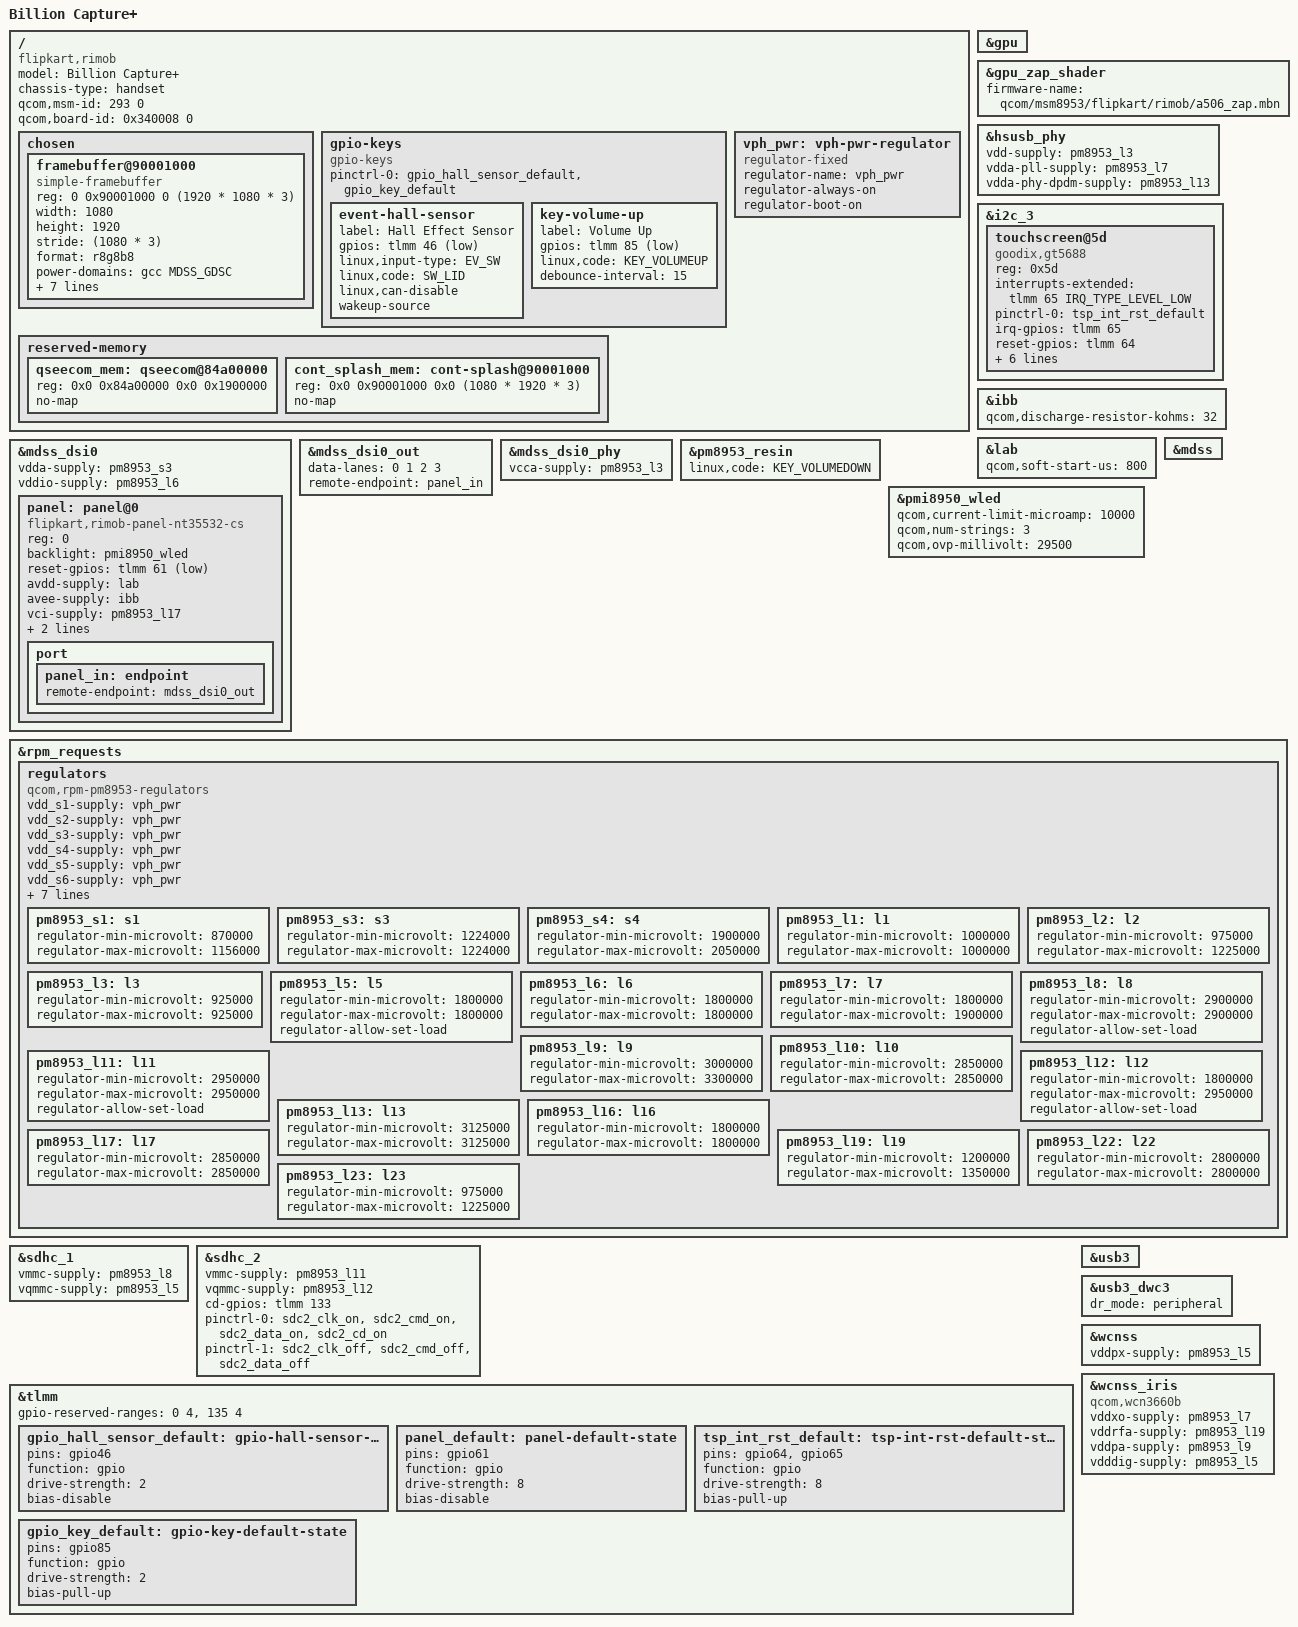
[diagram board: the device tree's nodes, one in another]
// SPDX-License-Identifier: BSD-3-Clause
/*
 * Copyright (c) 2025, Cristian Cozzolino
 */
/dts-v1/;

#include "msm8953.dtsi"
#include "pm8953.dtsi"
#include "pmi8950.dtsi"

/delete-node/ &cont_splash_mem;
/delete-node/ &qseecom_mem;

/ {
	model = "Billion Capture+";
	compatible = "flipkart,rimob", "qcom,msm8953";
	chassis-type = "handset";
	qcom,msm-id = <293 0>;
	qcom,board-id = <0x340008 0>;

	chosen {
		#address-cells = <2>;
		#size-cells = <2>;
		ranges;

		framebuffer@90001000 {
			compatible = "simple-framebuffer";
			reg = <0 0x90001000 0 (1920 * 1080 * 3)>;

			width = <1080>;
			height = <1920>;
			stride = <(1080 * 3)>;
			format = "r8g8b8";

			power-domains = <&gcc MDSS_GDSC>;

			clocks = <&gcc GCC_MDSS_AHB_CLK>,
				 <&gcc GCC_MDSS_AXI_CLK>,
				 <&gcc GCC_MDSS_VSYNC_CLK>,
				 <&gcc GCC_MDSS_MDP_CLK>,
				 <&gcc GCC_MDSS_BYTE0_CLK>,
				 <&gcc GCC_MDSS_PCLK0_CLK>,
				 <&gcc GCC_MDSS_ESC0_CLK>;
		};
	};

	gpio-keys {
		compatible = "gpio-keys";

		pinctrl-0 = <&gpio_hall_sensor_default>, <&gpio_key_default>;
		pinctrl-names = "default";

		event-hall-sensor {
			label = "Hall Effect Sensor";
			gpios = <&tlmm 46 GPIO_ACTIVE_LOW>;
			linux,input-type = <EV_SW>;
			linux,code = <SW_LID>;
			linux,can-disable;
			wakeup-source;
		};

		key-volume-up {
			label = "Volume Up";
			gpios = <&tlmm 85 GPIO_ACTIVE_LOW>;
			linux,code = <KEY_VOLUMEUP>;
			debounce-interval = <15>;
		};
	};

	reserved-memory {
		qseecom_mem: qseecom@84a00000 {
			reg = <0x0 0x84a00000 0x0 0x1900000>;
			no-map;
		};

		cont_splash_mem: cont-splash@90001000 {
			reg = <0x0 0x90001000 0x0 (1080 * 1920 * 3)>;
			no-map;
		};
	};

	vph_pwr: vph-pwr-regulator {
		compatible = "regulator-fixed";
		regulator-name = "vph_pwr";
		regulator-always-on;
		regulator-boot-on;
	};
};

&gpu {
	status = "okay";
};

&gpu_zap_shader {
	firmware-name = "qcom/msm8953/flipkart/rimob/a506_zap.mbn";
};

&hsusb_phy {
	vdd-supply = <&pm8953_l3>;
	vdda-pll-supply = <&pm8953_l7>;
	vdda-phy-dpdm-supply = <&pm8953_l13>;

	status = "okay";
};

&i2c_3 {
	status = "okay";

	touchscreen@5d {
		compatible = "goodix,gt5688";
		reg = <0x5d>;

		interrupts-extended = <&tlmm 65 IRQ_TYPE_LEVEL_LOW>;

		pinctrl-0 = <&tsp_int_rst_default>;
		pinctrl-names = "default";

		irq-gpios = <&tlmm 65 GPIO_ACTIVE_HIGH>;
		reset-gpios = <&tlmm 64 GPIO_ACTIVE_HIGH>;

		VDDIO-supply = <&pm8953_l6>;
		AVDD28-supply = <&pm8953_l10>;

		touchscreen-size-x = <1080>;
		touchscreen-size-y = <1920>;
		touchscreen-inverted-x;
		touchscreen-inverted-y;
	};
};

&ibb {
	qcom,discharge-resistor-kohms = <32>;
};

&lab {
	qcom,soft-start-us = <800>;
};

&mdss {
	status = "okay";
};

&mdss_dsi0 {
	vdda-supply = <&pm8953_s3>;
	vddio-supply = <&pm8953_l6>;

	status = "okay";

	panel: panel@0 {
		compatible = "flipkart,rimob-panel-nt35532-cs";
		reg = <0>;

		backlight = <&pmi8950_wled>;
		reset-gpios = <&tlmm 61 GPIO_ACTIVE_LOW>;
		avdd-supply = <&lab>;
		avee-supply = <&ibb>;
		vci-supply = <&pm8953_l17>;
		vddi-supply = <&pm8953_l6>;

		pinctrl-0 = <&panel_default>;
		pinctrl-names = "default";

		port {
			panel_in: endpoint {
				remote-endpoint = <&mdss_dsi0_out>;
			};
		};
	};
};

&mdss_dsi0_out {
	data-lanes = <0 1 2 3>;
	remote-endpoint = <&panel_in>;
};

&mdss_dsi0_phy {
	vcca-supply = <&pm8953_l3>;

	status = "okay";
};

&pm8953_resin {
	linux,code = <KEY_VOLUMEDOWN>;
	status = "okay";
};

&pmi8950_wled {
	qcom,current-limit-microamp = <10000>;
	qcom,num-strings = <3>;
	qcom,ovp-millivolt = <29500>;

	status = "okay";
};

&rpm_requests {
	regulators {
		compatible = "qcom,rpm-pm8953-regulators";
		vdd_s1-supply = <&vph_pwr>;
		vdd_s2-supply = <&vph_pwr>;
		vdd_s3-supply = <&vph_pwr>;
		vdd_s4-supply = <&vph_pwr>;
		vdd_s5-supply = <&vph_pwr>;
		vdd_s6-supply = <&vph_pwr>;
		vdd_s7-supply = <&vph_pwr>;
		vdd_l1-supply = <&pm8953_s3>;
		vdd_l2_l3-supply = <&pm8953_s3>;
		vdd_l4_l5_l6_l7_l16_l19-supply = <&pm8953_s4>;
		vdd_l8_l11_l12_l13_l14_l15-supply = <&vph_pwr>;
		vdd_l9_l10_l17_l18_l22-supply = <&vph_pwr>;
		vdd_l23-supply = <&pm8953_s3>;

		pm8953_s1: s1 {
			regulator-min-microvolt = <870000>;
			regulator-max-microvolt = <1156000>;
		};

		pm8953_s3: s3 {
			regulator-min-microvolt = <1224000>;
			regulator-max-microvolt = <1224000>;
		};

		pm8953_s4: s4 {
			regulator-min-microvolt = <1900000>;
			regulator-max-microvolt = <2050000>;
		};

		pm8953_l1: l1 {
			regulator-min-microvolt = <1000000>;
			regulator-max-microvolt = <1000000>;
		};

		pm8953_l2: l2 {
			regulator-min-microvolt = <975000>;
			regulator-max-microvolt = <1225000>;
		};

		pm8953_l3: l3 {
			regulator-min-microvolt = <925000>;
			regulator-max-microvolt = <925000>;
		};

		pm8953_l5: l5 {
			regulator-min-microvolt = <1800000>;
			regulator-max-microvolt = <1800000>;
			regulator-allow-set-load;
		};

		pm8953_l6: l6 {
			regulator-min-microvolt = <1800000>;
			regulator-max-microvolt = <1800000>;
		};

		pm8953_l7: l7 {
			regulator-min-microvolt = <1800000>;
			regulator-max-microvolt = <1900000>;
		};

		pm8953_l8: l8 {
			regulator-min-microvolt = <2900000>;
			regulator-max-microvolt = <2900000>;
			regulator-allow-set-load;
		};

		pm8953_l9: l9 {
			regulator-min-microvolt = <3000000>;
			regulator-max-microvolt = <3300000>;
		};

		pm8953_l10: l10 {
			regulator-min-microvolt = <2850000>;
			regulator-max-microvolt = <2850000>;
		};

		pm8953_l11: l11 {
			regulator-min-microvolt = <2950000>;
			regulator-max-microvolt = <2950000>;
			regulator-allow-set-load;
		};

		pm8953_l12: l12 {
			regulator-min-microvolt = <1800000>;
			regulator-max-microvolt = <2950000>;
			regulator-allow-set-load;
		};

		pm8953_l13: l13 {
			regulator-min-microvolt = <3125000>;
			regulator-max-microvolt = <3125000>;
		};

		pm8953_l16: l16 {
			regulator-min-microvolt = <1800000>;
			regulator-max-microvolt = <1800000>;
		};

		pm8953_l17: l17 {
			regulator-min-microvolt = <2850000>;
			regulator-max-microvolt = <2850000>;
		};

		pm8953_l19: l19 {
			regulator-min-microvolt = <1200000>;
			regulator-max-microvolt = <1350000>;
		};

		pm8953_l22: l22 {
			regulator-min-microvolt = <2800000>;
			regulator-max-microvolt = <2800000>;
		};

		pm8953_l23: l23 {
			regulator-min-microvolt = <975000>;
			regulator-max-microvolt = <1225000>;
		};
	};
};

&sdhc_1 {
	vmmc-supply = <&pm8953_l8>;
	vqmmc-supply = <&pm8953_l5>;

	status = "okay";
};

&sdhc_2 {
	vmmc-supply = <&pm8953_l11>;
	vqmmc-supply = <&pm8953_l12>;

	cd-gpios = <&tlmm 133 GPIO_ACTIVE_HIGH>;

	pinctrl-0 = <&sdc2_clk_on &sdc2_cmd_on &sdc2_data_on &sdc2_cd_on>;
	pinctrl-1 = <&sdc2_clk_off &sdc2_cmd_off &sdc2_data_off>;
	pinctrl-names = "default", "sleep";

	status = "okay";
};

&tlmm {
	gpio-reserved-ranges = <0 4>, <135 4>;

	gpio_hall_sensor_default: gpio-hall-sensor-default-state {
		pins = "gpio46";
		function = "gpio";
		drive-strength = <2>;
		bias-disable;
	};

	panel_default: panel-default-state {
		pins = "gpio61";
		function = "gpio";
		drive-strength = <8>;
		bias-disable;
	};

	tsp_int_rst_default: tsp-int-rst-default-state {
		pins = "gpio64", "gpio65";
		function = "gpio";
		drive-strength = <8>;
		bias-pull-up;
	};

	gpio_key_default: gpio-key-default-state {
		pins = "gpio85";
		function = "gpio";
		drive-strength = <2>;
		bias-pull-up;
	};
};

&usb3 {
	status = "okay";
};

&usb3_dwc3 {
	dr_mode = "peripheral";
};

&wcnss {
	vddpx-supply = <&pm8953_l5>;

	status = "okay";
};

&wcnss_iris {
	compatible = "qcom,wcn3660b";

	vddxo-supply = <&pm8953_l7>;
	vddrfa-supply = <&pm8953_l19>;
	vddpa-supply = <&pm8953_l9>;
	vdddig-supply = <&pm8953_l5>;
};
